# apollo3p register map
Vendor: Ambiq Micro; Series: Apollo; File version: 1.0
CPU: CM4 r1p0, little endian, MPU, FPU, I-cache, D-cache, VTOR, ITCM, DTCM, 3 interrupt priority bits, 0 interrupts
Registers are 32-bit, read-write, reset 0x0 unless marked. A register's access mark holds for its fields unless they carry their own. Offsets are from the block's base; [hi:lo] are bit positions; {n}, {i} and the like mark numbered series; 'fields as' and 'values as' point back to an identical list.

## CTIMER (part 1 of 3) — Counter/Timer
Base 0x40008000
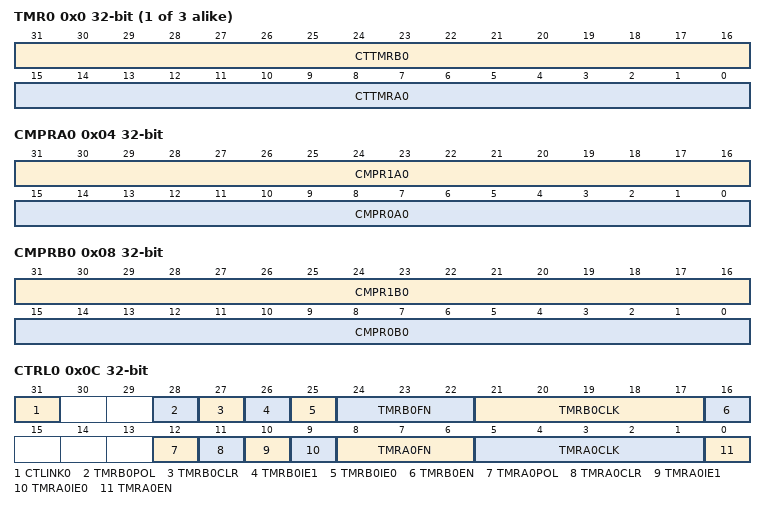
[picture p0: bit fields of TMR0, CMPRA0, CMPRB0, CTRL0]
{0x0+0x20*i} TMR{i} (i=0..2) — This register holds the running time or event count for CTIMER {i}. This is either for each 16 bit half or for the whole 32 bit count when the pair is linked. If the pair is not linked, they can be running on separate clocks and are completely independent.
  [31:16] CTTMRB{i} — Counter/Timer B{i}.
  [15:0] CTTMRA{i} — Counter/Timer A{i}.
0x04 CMPRA0 — This contains the Compare limits for timer 0 half A.
  [31:16] CMPR1A0 — Counter/Timer A0 Compare Register 1. Holds the upper limit for timer half A.
  [15:0] CMPR0A0 — Counter/Timer A0 Compare Register 0. Holds the lower limit for timer half A.
0x08 CMPRB0 — This contains the Compare limits for timer 0 B half.
  [31:16] CMPR1B0 — Counter/Timer B0 Compare Register 1. Holds the upper limit for timer half B.
  [15:0] CMPR0B0 — Counter/Timer B0 Compare Register 0. Holds the lower limit for timer half B.
0x0C CTRL0 — This includes the Control bit fields for both halves of timer 0.
  [31] CTLINK0 — Counter/Timer A0/B0 Link bit.
    0=TWO_16BIT_TIMERS (Use A0/B0 timers as two independent 16-bit timers (default).); 1=32BIT_TIMER (Link A0/B0 timers into a single 32-bit timer.)
  [28] TMRB0POL — Counter/Timer B0 output polarity.
    0=NORMAL (The polarity of the TMRPINB0 pin is the same as the timer output.); 1=INVERTED (The polarity of the TMRPINB0 pin is the inverse of the timer output.)
  [27] TMRB0CLR — Counter/Timer B0 Clear bit.
    0=RUN (Allow counter/timer B0 to run); 1=CLEAR (Holds counter/timer B0 at 0x0000.)
  [26] TMRB0IE1 — Counter/Timer B0 Interrupt Enable bit for COMPR1.
    0=DIS (Disable counter/timer B0 from generating an interrupt based on COMPR1.); 1=EN (Enable counter/timer B0 to generate an interrupt based on COMPR1.)
  [25] TMRB0IE0 — Counter/Timer B0 Interrupt Enable bit for COMPR0.
    0=DIS (Disable counter/timer B0 from generating an interrupt based on COMPR0.); 1=EN (Enable counter/timer B0 to generate an interrupt based on COMPR0)
  [24:22] TMRB0FN — Counter/Timer B0 Function Select.
    0=SINGLECOUNT (Single count (output toggles and sticks). Count to CMPR0B0, stop.); 1=REPEATEDCOUNT (Repeated count (periodic 1-clock-cycle-wide pulses). Count to CMPR0B0, restart.); 2=PULSE_ONCE (Pulse once (aka one-shot). Count to CMPR0B0, assert, count to CMPR1B0, deassert, stop.); 3=PULSE_CONT (Pulse continuously. Count to CMPR0B0, assert, count to CMPR1B0, deassert, restart.); 4=SINGLEPATTERN; 5=REPEATPATTERN (Repeated pattern.); 6=CONTINUOUS (Continuous run (aka Free Run). Count continuously.); 7=ALTPWN (Alternate PWM)
  [21:17] TMRB0CLK — Counter/Timer B0 Clock Select.
    0=TMRPIN (Clock source is TMRPINB.); 1=HFRC_DIV4 (Clock source is the HFRC / 4); 2=HFRC_DIV16 (Clock source is HFRC / 16); 3=HFRC_DIV256 (Clock source is HFRC / 256); 4=HFRC_DIV1024 (Clock source is HFRC / 1024); 5=HFRC_DIV4K (Clock source is HFRC / 4096); 6=XT (Clock source is the XT (uncalibrated).); 7=XT_DIV2 (Clock source is XT / 2); 8=XT_DIV16 (Clock source is XT / 16); 9=XT_DIV128 (Clock source is XT / 128); 10=LFRC_DIV2 (Clock source is LFRC / 2); 11=LFRC_DIV32 (Clock source is LFRC / 32); 12=LFRC_DIV1K (Clock source is LFRC / 1024); 13=LFRC (Clock source is LFRC); 14=RTC_100HZ (Clock source is 100 Hz from the current RTC oscillator.); 15=HCLK_DIV4 (Clock source is HCLK / 4 (note: this clock is only available when MCU is in active mode)); 16=XT_DIV4 (Clock source is XT / 4); 17=XT_DIV8 (Clock source is XT / 8); 18=XT_DIV32 (Clock source is XT / 32); 20=CTMRA0 (Clock source is CTIMERA0 OUT.); 21=CTMRB1 (Clock source is CTIMERB1 OUT.); 22=CTMRA1 (Clock source is CTIMERA1 OUT.); 23=CTMRA2 (Clock source is CTIMERA2 OUT.); {v}=CTMRB{v-22} (Clock source is CTIMERB{v-22} OUT.) (v=24..28); 29=BUCKBLE (Clock source is BLE buck converter TON pulses.); 30=BUCKB (Clock source is Memory buck converter TON pulses.); 31=BUCKA (Clock source is CPU buck converter TON pulses.)
  [16] TMRB0EN — Counter/Timer B0 Enable bit.
    0=DIS (Counter/Timer B0 Disable.); 1=EN (Counter/Timer B0 Enable.)
  [12] TMRA0POL — Counter/Timer A0 output polarity.
    0=NORMAL (The polarity of the TMRPINA0 pin is the same as the timer output.); 1=INVERTED (The polarity of the TMRPINA0 pin is the inverse of the timer output.)
  [11] TMRA0CLR — Counter/Timer A0 Clear bit.
    0=RUN (Allow counter/timer A0 to run); 1=CLEAR (Holds counter/timer A0 at 0x0000.)
  [10] TMRA0IE1 — Counter/Timer A0 Interrupt Enable bit based on COMPR1.
    0=DIS (Disable counter/timer A0 from generating an interrupt based on COMPR1.); 1=EN (Enable counter/timer A0 to generate an interrupt based on COMPR1.)
  [9] TMRA0IE0 — Counter/Timer A0 Interrupt Enable bit based on COMPR0.
    0=DIS (Disable counter/timer A0 from generating an interrupt based on COMPR0.); 1=EN (Enable counter/timer A0 to generate an interrupt based on COMPR0.)
  [8:6] TMRA0FN — Counter/Timer A0 Function Select.
    0=SINGLECOUNT (Single count (output toggles and sticks). Count to CMPR0A0, stop.); 1=REPEATEDCOUNT (Repeated count (periodic 1-clock-cycle-wide pulses). Count to CMPR0A0, restart.); 2=PULSE_ONCE (Pulse once (aka one-shot). Count to CMPR0A0, assert, count to CMPR1A0, deassert, stop.); 3=PULSE_CONT (Pulse continuously. Count to CMPR0A0, assert, count to CMPR1A0, deassert, restart.); 4=SINGLEPATTERN; 5=REPEATPATTERN (Repeated pattern.); 6=CONTINUOUS (Continuous run (aka Free Run). Count continuously.); 7=ALTPWN (Alternate PWM)
  [5:1] TMRA0CLK — Counter/Timer A0 Clock Select.
    0=TMRPIN (Clock source is TMRPINA.); 1=HFRC_DIV4 (Clock source is the HFRC / 4); 2=HFRC_DIV16 (Clock source is HFRC / 16); 3=HFRC_DIV256 (Clock source is HFRC / 256); 4=HFRC_DIV1024 (Clock source is HFRC / 1024); 5=HFRC_DIV4K (Clock source is HFRC / 4096); 6=XT (Clock source is the XT (uncalibrated).); 7=XT_DIV2 (Clock source is XT / 2); 8=XT_DIV16 (Clock source is XT / 16); 9=XT_DIV128 (Clock source is XT / 128); 10=LFRC_DIV2 (Clock source is LFRC / 2); 11=LFRC_DIV32 (Clock source is LFRC / 32); 12=LFRC_DIV1K (Clock source is LFRC / 1024); 13=LFRC (Clock source is LFRC); 14=RTC_100HZ (Clock source is 100 Hz from the current RTC oscillator.); 15=HCLK_DIV4 (Clock source is HCLK / 4 (note: this clock is only available when MCU is in active mode)); 16=XT_DIV4 (Clock source is XT / 4); 17=XT_DIV8 (Clock source is XT / 8); 18=XT_DIV32 (Clock source is XT / 32); 20=CTMRB0 (Clock source is CTIMERB0 OUT.); 21=CTMRA1 (Clock source is CTIMERA1 OUT.); 22=CTMRB1 (Clock source is CTIMERB1 OUT.); 23=CTMRA2 (Clock source is CTIMERA2 OUT.); {v}=CTMRB{v-22} (Clock source is CTIMERB{v-22} OUT.) (v=24..28); 29=BUCKBLE (Clock source is BLE buck converter TON pulses.); 30=BUCKB (Clock source is Memory buck converter TON pulses.); 31=BUCKA (Clock source is CPU buck converter TON pulses.)
  [0] TMRA0EN — Counter/Timer A0 Enable bit.
    0=DIS (Counter/Timer A0 Disable.); 1=EN (Counter/Timer A0 Enable.)
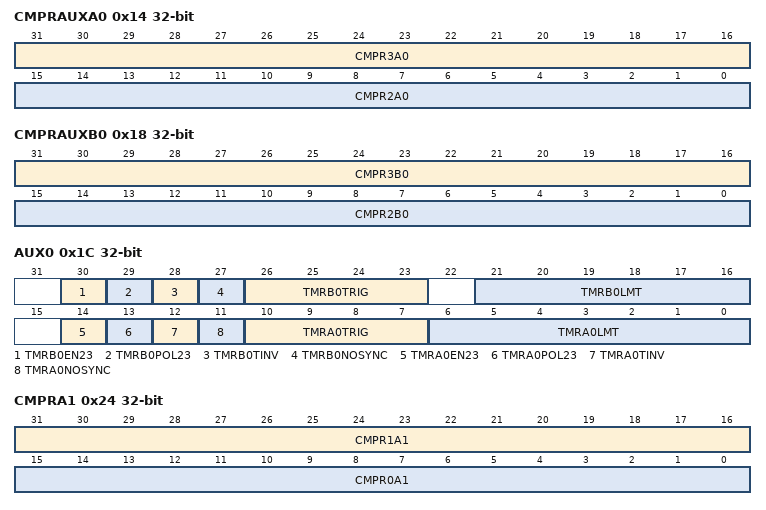
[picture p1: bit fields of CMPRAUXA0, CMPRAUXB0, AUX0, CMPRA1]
0x14 CMPRAUXA0 — Enhanced compare limits for timer half A. This is valid if timer 0 is set to function 4 and function 5.
  [31:16] CMPR3A0 — Counter/Timer A0 Compare Register 3. Holds the upper limit for timer half A.
  [15:0] CMPR2A0 — Counter/Timer A0 Compare Register 2. Holds the lower limit for timer half A.
0x18 CMPRAUXB0 — Enhanced compare limits for timer half B. This is valid if timer 0 is set to function 4 and function 5.
  [31:16] CMPR3B0 — Counter/Timer B0 Compare Register 3. Holds the upper limit for timer half B.
  [15:0] CMPR2B0 — Counter/Timer B0 Compare Register 2. Holds the lower limit for timer half B.
0x1C AUX0 — Control bit fields for both halves of timer 0.
  [30] TMRB0EN23 — Counter/Timer B0 Upper compare enable.
    1=DIS (Disable enhanced functions.); 0=EN (Enable enhanced functions.)
  [29] TMRB0POL23 — Upper output polarity
    0=NORM (Upper output normal polarity); 1=INV (Upper output inverted polarity.)
  [28] TMRB0TINV — Counter/Timer B0 Invert on trigger.
    0=DIS (Disable invert on trigger); 1=EN (Enable invert on trigger)
  [27] TMRB0NOSYNC — Source clock synchronization control.
    0=DIS (Synchronization on source clock); 1=NOSYNC (No synchronization on source clock)
  [26:23] TMRB0TRIG — Counter/Timer B0 Trigger Select.
    0=DIS (Trigger source is disabled.); 1=A0OUT (Trigger source is CTIMERA0 OUT.); 2=B3OUT (Trigger source is CTIMERB3 OUT.); 3=A3OUT (Trigger source is CTIMERA3 OUT.); 4=B2OUT (Trigger source is CTIMERB2 OUT.); 5=B5OUT (Trigger source is CTIMERB5 OUT.); 6=A4OUT (Trigger source is CTIMERA4 OUT.); 7=B4OUT (Trigger source is CTIMERB4 OUT.); 8=B3OUT2 (Trigger source is CTIMERB3 OUT2.); 9=A3OUT2 (Trigger source is CTIMERA3 OUT2.); 10=B7OUT2 (Trigger source is CTIMERB7 OUT2.); 11=A2OUT2 (Trigger source is CTIMERA2 OUT2.); 12=A6OUT2DUAL (Trigger source is CTIMERA6 OUT2, dual edge.); 13=A7OUT2DUAL (Trigger source is CTIMERA7 OUT2, dual edge.); 14=B5OUT2DUAL (Trigger source is CTIMERB5 OUT2, dual edge.); 15=A5OUT2DUAL (Trigger source is CTIMERA5 OUT2, dual edge.)
  [21:16] TMRB0LMT — Counter/Timer B0 Pattern Limit Count.
  [14] TMRA0EN23 — Counter/Timer A0 Upper compare enable.
    values as TMRB0EN23
  [13] TMRA0POL23 — Counter/Timer A0 Upper output polarity
    values as TMRB0POL23
  [12] TMRA0TINV — Counter/Timer A0 Invert on trigger.
    values as TMRB0TINV
  [11] TMRA0NOSYNC — Source clock synchronization control.
    values as TMRB0NOSYNC
  [10:7] TMRA0TRIG — Counter/Timer A0 Trigger Select.
    0=DIS (Trigger source is disabled.); 1=B0OUT (Trigger source is CTIMERB0 OUT.); 2=B3OUT (Trigger source is CTIMERB3 OUT.); 3=A3OUT (Trigger source is CTIMERA3 OUT.); 4=A1OUT (Trigger source is CTIMERA1 OUT.); 5=B1OUT (Trigger source is CTIMERB1 OUT.); 6=A5OUT (Trigger source is CTIMERA5 OUT.); 7=B5OUT (Trigger source is CTIMERB5 OUT.); 8=B3OUT2 (Trigger source is CTIMERB3 OUT2.); 9=A3OUT2 (Trigger source is CTIMERA3 OUT2.); 10=B6OUT2 (Trigger source is CTIMERB6 OUT2.); 11=A2OUT2 (Trigger source is CTIMERA2 OUT2.); 12=A6OUT2DUAL (Trigger source is CTIMERA6 OUT2, dual edge.); 13=A7OUT2DUAL (Trigger source is CTIMERA7 OUT2, dual edge.); 14=B4OUT2DUAL (Trigger source is CTIMERB4 OUT2, dual edge.); 15=A4OUT2DUAL (Trigger source is CTIMERA4 OUT2, dual edge.)
  [6:0] TMRA0LMT — Counter/Timer A0 Pattern Limit Count.
0x24 CMPRA1 — This contains the Compare limits for timer 1 A half.
  [31:16] CMPR1A1 — Counter/Timer A1 Compare Register 1.
  [15:0] CMPR0A1 — Counter/Timer A1 Compare Register 0.
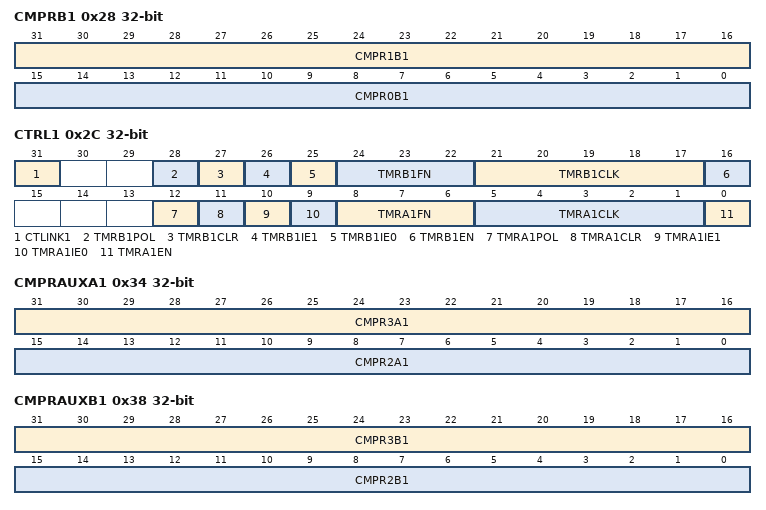
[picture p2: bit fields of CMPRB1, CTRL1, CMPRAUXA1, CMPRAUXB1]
0x28 CMPRB1 — This contains the Compare limits for timer 1 B half.
  [31:16] CMPR1B1 — Counter/Timer B1 Compare Register 1.
  [15:0] CMPR0B1 — Counter/Timer B1 Compare Register 0.
0x2C CTRL1 — This includes the Control bit fields for both halves of timer 1.
  [31] CTLINK1 — Counter/Timer A1/B1 Link bit.
    0=TWO_16BIT_TIMERS (Use A1/B1 timers as two independent 16-bit timers (default).); 1=32BIT_TIMER (Link A1/B1 timers into a single 32-bit timer.)
  [28] TMRB1POL — Counter/Timer B1 output polarity.
    0=NORMAL (The polarity of the TMRPINB1 pin is the same as the timer output.); 1=INVERTED (The polarity of the TMRPINB1 pin is the inverse of the timer output.)
  [27] TMRB1CLR — Counter/Timer B1 Clear bit.
    0=RUN (Allow counter/timer B1 to run); 1=CLEAR (Holds counter/timer B1 at 0x0000.)
  [26] TMRB1IE1 — Counter/Timer B1 Interrupt Enable bit for COMPR1.
    0=DIS (Disable counter/timer B1 from generating an interrupt based on COMPR1.); 1=EN (Enable counter/timer B1 to generate an interrupt based on COMPR1.)
  [25] TMRB1IE0 — Counter/Timer B1 Interrupt Enable bit for COMPR0.
    0=DIS (Disable counter/timer B1 from generating an interrupt based on COMPR0.); 1=EN (Enable counter/timer B1 to generate an interrupt based on COMPR0)
  [24:22] TMRB1FN — Counter/Timer B1 Function Select.
    0=SINGLECOUNT (Single count (output toggles and sticks). Count to CMPR0B1, stop.); 1=REPEATEDCOUNT (Repeated count (periodic 1-clock-cycle-wide pulses). Count to CMPR0B1, restart.); 2=PULSE_ONCE (Pulse once (aka one-shot). Count to CMPR0B1, assert, count to CMPR1B1, deassert, stop.); 3=PULSE_CONT (Pulse continuously. Count to CMPR0B1, assert, count to CMPR1B1, deassert, restart.); 4=SINGLEPATTERN; 5=REPEATPATTERN (Repeated pattern.); 6=CONTINUOUS (Continuous run (aka Free Run). Count continuously.); 7=ALTPWN (Alternate PWM)
  [21:17] TMRB1CLK — Counter/Timer B1 Clock Select.
    0=TMRPIN (Clock source is TMRPINB.); 1=HFRC_DIV4 (Clock source is the HFRC / 4); 2=HFRC_DIV16 (Clock source is HFRC / 16); 3=HFRC_DIV256 (Clock source is HFRC / 256); 4=HFRC_DIV1024 (Clock source is HFRC / 1024); 5=HFRC_DIV4K (Clock source is HFRC / 4096); 6=XT (Clock source is the XT (uncalibrated).); 7=XT_DIV2 (Clock source is XT / 2); 8=XT_DIV16 (Clock source is XT / 16); 9=XT_DIV128 (Clock source is XT / 128); 10=LFRC_DIV2 (Clock source is LFRC / 2); 11=LFRC_DIV32 (Clock source is LFRC / 32); 12=LFRC_DIV1K (Clock source is LFRC / 1024); 13=LFRC (Clock source is LFRC); 14=RTC_100HZ (Clock source is 100 Hz from the current RTC oscillator.); 15=HCLK_DIV4 (Clock source is HCLK / 4 (note: this clock is only available when MCU is in active mode)); 16=XT_DIV4 (Clock source is XT / 4); 17=XT_DIV8 (Clock source is XT / 8); 18=XT_DIV32 (Clock source is XT / 32); 20=CTMRA1 (Clock source is CTIMERA1 OUT.); 21=CTMRA0 (Clock source is CTIMERA0 OUT.); 22=CTMRB0 (Clock source is CTIMERB0 OUT.); 23=CTMRA2 (Clock source is CTIMERA2 OUT.); {v}=CTMRB{v-22} (Clock source is CTIMERB{v-22} OUT.) (v=24..28); 29=BUCKBLE (Clock source is BLE buck converter TON pulses.); 30=BUCKB (Clock source is Memory buck converter TON pulses.); 31=BUCKA (Clock source is CPU buck converter TON pulses.)
  [16] TMRB1EN — Counter/Timer B1 Enable bit.
    0=DIS (Counter/Timer B1 Disable.); 1=EN (Counter/Timer B1 Enable.)
  [12] TMRA1POL — Counter/Timer A1 output polarity.
    0=NORMAL (The polarity of the TMRPINA1 pin is the same as the timer output.); 1=INVERTED (The polarity of the TMRPINA1 pin is the inverse of the timer output.)
  [11] TMRA1CLR — Counter/Timer A1 Clear bit.
    0=RUN (Allow counter/timer A1 to run); 1=CLEAR (Holds counter/timer A1 at 0x0000.)
  [10] TMRA1IE1 — Counter/Timer A1 Interrupt Enable bit based on COMPR1.
    0=DIS (Disable counter/timer A1 from generating an interrupt based on COMPR1.); 1=EN (Enable counter/timer A1 to generate an interrupt based on COMPR1.)
  [9] TMRA1IE0 — Counter/Timer A1 Interrupt Enable bit based on COMPR0.
    0=DIS (Disable counter/timer A1 from generating an interrupt based on COMPR0.); 1=EN (Enable counter/timer A1 to generate an interrupt based on COMPR0.)
  [8:6] TMRA1FN — Counter/Timer A1 Function Select.
    0=SINGLECOUNT (Single count (output toggles and sticks). Count to CMPR0A1, stop.); 1=REPEATEDCOUNT (Repeated count (periodic 1-clock-cycle-wide pulses). Count to CMPR0A1, restart.); 2=PULSE_ONCE (Pulse once (aka one-shot). Count to CMPR0A1, assert, count to CMPR1A1, deassert, stop.); 3=PULSE_CONT (Pulse continuously. Count to CMPR0A1, assert, count to CMPR1A1, deassert, restart.); 4=SINGLEPATTERN; 5=REPEATPATTERN (Repeated pattern.); 6=CONTINUOUS (Continuous run (aka Free Run). Count continuously.); 7=ALTPWN (Alternate PWM)
  [5:1] TMRA1CLK — Counter/Timer A1 Clock Select.
    0=TMRPIN (Clock source is TMRPINA.); 1=HFRC_DIV4 (Clock source is the HFRC / 4); 2=HFRC_DIV16 (Clock source is HFRC / 16); 3=HFRC_DIV256 (Clock source is HFRC / 256); 4=HFRC_DIV1024 (Clock source is HFRC / 1024); 5=HFRC_DIV4K (Clock source is HFRC / 4096); 6=XT (Clock source is the XT (uncalibrated).); 7=XT_DIV2 (Clock source is XT / 2); 8=XT_DIV16 (Clock source is XT / 16); 9=XT_DIV128 (Clock source is XT / 128); 10=LFRC_DIV2 (Clock source is LFRC / 2); 11=LFRC_DIV32 (Clock source is LFRC / 32); 12=LFRC_DIV1K (Clock source is LFRC / 1024); 13=LFRC (Clock source is LFRC); 14=RTC_100HZ (Clock source is 100 Hz from the current RTC oscillator.); 15=HCLK_DIV4 (Clock source is HCLK / 4 (note: this clock is only available when MCU is in active mode)); 16=XT_DIV4 (Clock source is XT / 4); 17=XT_DIV8 (Clock source is XT / 8); 18=XT_DIV32 (Clock source is XT / 32); 20=CTMRB1 (Clock source is CTIMERB1 OUT.); 21=CTMRA0 (Clock source is CTIMERA0 OUT.); 22=CTMRB0 (Clock source is CTIMERB0 OUT.); 23=CTMRA2 (Clock source is CTIMERA2 OUT.); {v}=CTMRB{v-22} (Clock source is CTIMERB{v-22} OUT.) (v=24..28); 29=BUCKBLE (Clock source is BLE buck converter TON pulses.); 30=BUCKB (Clock source is Memory buck converter TON pulses.); 31=BUCKA (Clock source is CPU buck converter TON pulses.)
  [0] TMRA1EN — Counter/Timer A1 Enable bit.
    0=DIS (Counter/Timer A1 Disable.); 1=EN (Counter/Timer A1 Enable.)
0x34 CMPRAUXA1 — Enhanced compare limits for timer half A. This is valid if timer 1 is set to function 4 and function 5.
  [31:16] CMPR3A1 — Counter/Timer A1 Compare Register 3. Holds the upper limit for timer half A.
  [15:0] CMPR2A1 — Counter/Timer A1 Compare Register 2. Holds the lower limit for timer half A.
0x38 CMPRAUXB1 — Enhanced compare limits for timer half B. This is valid if timer 1 is set to function 4 and function 5.
  [31:16] CMPR3B1 — Counter/Timer B1 Compare Register 3. Holds the upper limit for timer half B.
  [15:0] CMPR2B1 — Counter/Timer B1 Compare Register 2. Holds the lower limit for timer half B.
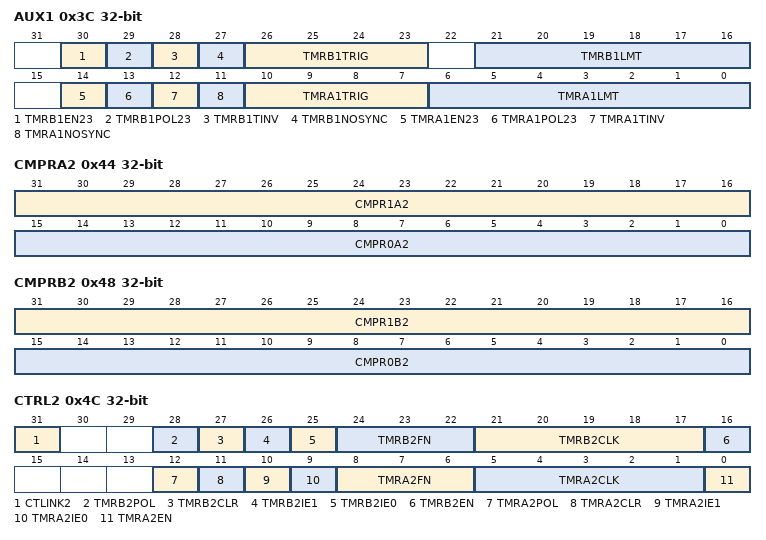
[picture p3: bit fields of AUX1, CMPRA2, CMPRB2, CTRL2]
0x3C AUX1 — Control bit fields for both halves of timer 0.
  [30] TMRB1EN23 — Counter/Timer B1 Upper compare enable.
    values as AUX0.TMRB0EN23
  [29] TMRB1POL23 — Upper output polarity
    values as AUX0.TMRB0POL23
  [28] TMRB1TINV — Counter/Timer B1 Invert on trigger.
    values as AUX0.TMRB0TINV
  [27] TMRB1NOSYNC — Source clock synchronization control.
    values as AUX0.TMRB0NOSYNC
  [26:23] TMRB1TRIG — Counter/Timer B1 Trigger Select.
    0=DIS (Trigger source is disabled.); 1=A1OUT (Trigger source is CTIMERA1 OUT.); 2=B3OUT (Trigger source is CTIMERB3 OUT.); 3=A3OUT (Trigger source is CTIMERA3 OUT.); 4=A6OUT (Trigger source is CTIMERA6 OUT.); 5=B6OUT (Trigger source is CTIMERB6 OUT.); 6=A0OUT (Trigger source is CTIMERA0 OUT.); 7=B0OUT (Trigger source is CTIMERB0 OUT.); 8=B3OUT2 (Trigger source is CTIMERB3 OUT2.); 9=A3OUT2 (Trigger source is CTIMERA3 OUT2.); 10=A4OUT2 (Trigger source is CTIMERA4 OUT2.); 11=B4OUT2 (Trigger source is CTIMERB4 OUT2.); 12=A6OUT2DUAL (Trigger source is CTIMERA6 OUT2, dual edge.); 13=A7OUT2DUAL (Trigger source is CTIMERA7 OUT2, dual edge.); 14=B5OUT2DUAL (Trigger source is CTIMERB5 OUT2, dual edge.); 15=A5OUT2DUAL (Trigger source is CTIMERA5 OUT2, dual edge.)
  [21:16] TMRB1LMT — Counter/Timer B1 Pattern Limit Count.
  [14] TMRA1EN23 — Counter/Timer A1 Upper compare enable.
    values as AUX0.TMRB0EN23
  [13] TMRA1POL23 — Counter/Timer A1 Upper output polarity
    0=NORMAL (Upper output normal polarity); 1=INV (Upper output inverted polarity.)
  [12] TMRA1TINV — Counter/Timer A1 Invert on trigger.
    values as AUX0.TMRB0TINV
  [11] TMRA1NOSYNC — Source clock synchronization control.
    values as AUX0.TMRB0NOSYNC
  [10:7] TMRA1TRIG — Counter/Timer A1 Trigger Select.
    0=DIS (Trigger source is disabled.); 1=B1OUT (Trigger source is CTIMERB1 OUT.); 2=B3OUT (Trigger source is CTIMERB3 OUT.); 3=A3OUT (Trigger source is CTIMERA3 OUT.); 4=A0OUT (Trigger source is CTIMERA0 OUT.); 5=B0OUT (Trigger source is CTIMERB0 OUT.); 6=A5OUT (Trigger source is CTIMERA5 OUT.); 7=B5OUT (Trigger source is CTIMERB5 OUT.); 8=B3OUT2 (Trigger source is CTIMERB3 OUT2.); 9=A3OUT2 (Trigger source is CTIMERA3 OUT2.); 10=A4OUT2 (Trigger source is CTIMERA4 OUT2.); 11=B4OUT2 (Trigger source is CTIMERB4 OUT2.); 12=A6OUT2DUAL (Trigger source is CTIMERA6 OUT2, dual edge.); 13=A7OUT2DUAL (Trigger source is CTIMERA7 OUT2, dual edge.); 14=B5OUT2DUAL (Trigger source is CTIMERB5 OUT2, dual edge.); 15=A5OUT2DUAL (Trigger source is CTIMERA5 OUT2, dual edge.)
  [6:0] TMRA1LMT — Counter/Timer A1 Pattern Limit Count.
0x44 CMPRA2 — This register holds the compare limits for timer 2 A half.
  [31:16] CMPR1A2 — Counter/Timer A2 Compare Register 1.
  [15:0] CMPR0A2 — Counter/Timer A2 Compare Register 0.
0x48 CMPRB2 — This register holds the compare limits for timer 2 B half.
  [31:16] CMPR1B2 — Counter/Timer B2 Compare Register 1.
  [15:0] CMPR0B2 — Counter/Timer B2 Compare Register 0.
0x4C CTRL2 — This register holds the control bit fields for both halves of timer 2.
  [31] CTLINK2 — Counter/Timer A2/B2 Link bit.
    0=TWO_16BIT_TIMERS (Use A2/B2 timers as two independent 16-bit timers (default).); 1=32BIT_TIMER (Link A2/B2 timers into a single 32-bit timer.)
  [28] TMRB2POL — Counter/Timer B2 output polarity.
    0=NORMAL (The polarity of the TMRPINB2 pin is the same as the timer output.); 1=INVERTED (The polarity of the TMRPINB2 pin is the inverse of the timer output.)
  [27] TMRB2CLR — Counter/Timer B2 Clear bit.
    0=RUN (Allow counter/timer B2 to run); 1=CLEAR (Holds counter/timer B2 at 0x0000.)
  [26] TMRB2IE1 — Counter/Timer B2 Interrupt Enable bit for COMPR1.
    0=DIS (Disable counter/timer B2 from generating an interrupt based on COMPR1.); 1=EN (Enable counter/timer B2 to generate an interrupt based on COMPR1.)
  [25] TMRB2IE0 — Counter/Timer B2 Interrupt Enable bit for COMPR0.
    0=DIS (Disable counter/timer B2 from generating an interrupt based on COMPR0.); 1=EN (Enable counter/timer B2 to generate an interrupt based on COMPR0)
  [24:22] TMRB2FN — Counter/Timer B2 Function Select.
    0=SINGLECOUNT (Single count (output toggles and sticks). Count to CMPR0B2, stop.); 1=REPEATEDCOUNT (Repeated count (periodic 1-clock-cycle-wide pulses). Count to CMPR0B2, restart.); 2=PULSE_ONCE (Pulse once (aka one-shot). Count to CMPR0B2, assert, count to CMPR1B2, deassert, stop.); 3=PULSE_CONT (Pulse continuously. Count to CMPR0B2, assert, count to CMPR1B2, deassert, restart.); 4=SINGLEPATTERN; 5=REPEATPATTERN (Repeated pattern.); 6=CONTINUOUS (Continuous run (aka Free Run). Count continuously.); 7=ALTPWN (Alternate PWM)
  [21:17] TMRB2CLK — Counter/Timer B2 Clock Select.
    0=TMRPIN (Clock source is TMRPINB.); 1=HFRC_DIV4 (Clock source is the HFRC / 4); 2=HFRC_DIV16 (Clock source is HFRC / 16); 3=HFRC_DIV256 (Clock source is HFRC / 256); 4=HFRC_DIV1024 (Clock source is HFRC / 1024); 5=HFRC_DIV4K (Clock source is HFRC / 4096); 6=XT (Clock source is the XT (uncalibrated).); 7=XT_DIV2 (Clock source is XT / 2); 8=XT_DIV16 (Clock source is XT / 16); 9=XT_DIV128 (Clock source is XT / 128); 10=LFRC_DIV2 (Clock source is LFRC / 2); 11=LFRC_DIV32 (Clock source is LFRC / 32); 12=LFRC_DIV1K (Clock source is LFRC / 1024); 13=LFRC (Clock source is LFRC); 14=RTC_100HZ (Clock source is 100 Hz from the current RTC oscillator.); 15=HCLK_DIV4 (Clock source is HCLK / 4 (note: this clock is only available when MCU is in active mode)); 16=XT_DIV4 (Clock source is XT / 4); 17=XT_DIV8 (Clock source is XT / 8); 18=XT_DIV32 (Clock source is XT / 32); 20=CTMRA2 (Clock source is CTIMERA2 OUT.); 21=CTMRB3 (Clock source is CTIMERA3 OUT.); 22=CTMRA3 (Clock source is CTIMERB3 OUT.); 23=CTMRA4 (Clock source is CTIMERA4 OUT.); 24=CTMRB4 (Clock source is CTIMERB4 OUT.); 25=CTMRB0 (Clock source is CTIMERB0 OUT.); 26=CTMRB1 (Clock source is CTIMERB1 OUT.); 27=CTMRB5 (Clock source is CTIMERB5 OUT.); 28=CTMRB6 (Clock source is CTIMERB6 OUT.); 29=BUCKBLE (Clock source is BLE buck converter TON pulses.); 30=BUCKB (Clock source is Memory buck converter TON pulses.); 31=BUCKA (Clock source is CPU buck converter TON pulses.)
  [16] TMRB2EN — Counter/Timer B2 Enable bit.
    0=DIS (Counter/Timer B2 Disable.); 1=EN (Counter/Timer B2 Enable.)
  [12] TMRA2POL — Counter/Timer A2 output polarity.
    0=NORMAL (The polarity of the TMRPINA2 pin is the same as the timer output.); 1=INVERTED (The polarity of the TMRPINA2 pin is the inverse of the timer output.)
  [11] TMRA2CLR — Counter/Timer A2 Clear bit.
    0=RUN (Allow counter/timer A2 to run); 1=CLEAR (Holds counter/timer A2 at 0x0000.)
  [10] TMRA2IE1 — Counter/Timer A2 Interrupt Enable bit based on COMPR1.
    0=DIS (Disable counter/timer A2 from generating an interrupt based on COMPR1.); 1=EN (Enable counter/timer A2 to generate an interrupt based on COMPR1.)
  [9] TMRA2IE0 — Counter/Timer A2 Interrupt Enable bit based on COMPR0.
    0=DIS (Disable counter/timer A2 from generating an interrupt based on COMPR0.); 1=EN (Enable counter/timer A2 to generate an interrupt based on COMPR0.)
  [8:6] TMRA2FN — Counter/Timer A2 Function Select.
    0=SINGLECOUNT (Single count (output toggles and sticks). Count to CMPR0A2, stop.); 1=REPEATEDCOUNT (Repeated count (periodic 1-clock-cycle-wide pulses). Count to CMPR0A2, restart.); 2=PULSE_ONCE (Pulse once (aka one-shot). Count to CMPR0A2, assert, count to CMPR1A2, deassert, stop.); 3=PULSE_CONT (Pulse continuously. Count to CMPR0A2, assert, count to CMPR1A2, deassert, restart.); 4=SINGLEPATTERN; 5=REPEATPATTERN (Repeated pattern.); 6=CONTINUOUS (Continuous run (aka Free Run). Count continuously.); 7=ALTPWN (Alternate PWM)
  [5:1] TMRA2CLK — Counter/Timer A2 Clock Select.
    0=TMRPIN (Clock source is TMRPINA.); 1=HFRC_DIV4 (Clock source is the HFRC / 4); 2=HFRC_DIV16 (Clock source is HFRC / 16); 3=HFRC_DIV256 (Clock source is HFRC / 256); 4=HFRC_DIV1024 (Clock source is HFRC / 1024); 5=HFRC_DIV4K (Clock source is HFRC / 4096); 6=XT (Clock source is the XT (uncalibrated).); 7=XT_DIV2 (Clock source is XT / 2); 8=XT_DIV16 (Clock source is XT / 16); 9=XT_DIV128 (Clock source is XT / 128); 10=LFRC_DIV2 (Clock source is LFRC / 2); 11=LFRC_DIV32 (Clock source is LFRC / 32); 12=LFRC_DIV1K (Clock source is LFRC / 1024); 13=LFRC (Clock source is LFRC); 14=RTC_100HZ (Clock source is 100 Hz from the current RTC oscillator.); 15=HCLK_DIV4 (Clock source is HCLK / 4 (note: this clock is only available when MCU is in active mode)); 16=XT_DIV4 (Clock source is XT / 4); 17=XT_DIV8 (Clock source is XT / 8); 18=XT_DIV32 (Clock source is XT / 32); 20=CTMRB2 (Clock source is CTIMERB2 OUT.); 21=CTMRB3 (Clock source is CTIMERA3 OUT.); 22=CTMRA3 (Clock source is CTIMERB3 OUT.); 23=CTMRA4 (Clock source is CTIMERA4 OUT.); 24=CTMRB4 (Clock source is CTIMERB4 OUT.); 25=CTMRB0 (Clock source is CTIMERB0 OUT.); 26=CTMRB1 (Clock source is CTIMERB1 OUT.); 27=CTMRB5 (Clock source is CTIMERB5 OUT.); 28=CTMRB6 (Clock source is CTIMERB6 OUT.); 29=BUCKBLE (Clock source is BLE buck converter TON pulses.); 30=BUCKB (Clock source is Memory buck converter TON pulses.); 31=BUCKA (Clock source is CPU buck converter TON pulses.)
  [0] TMRA2EN — Counter/Timer A2 Enable bit.
    0=DIS (Counter/Timer A2 Disable.); 1=EN (Counter/Timer A2 Enable.)
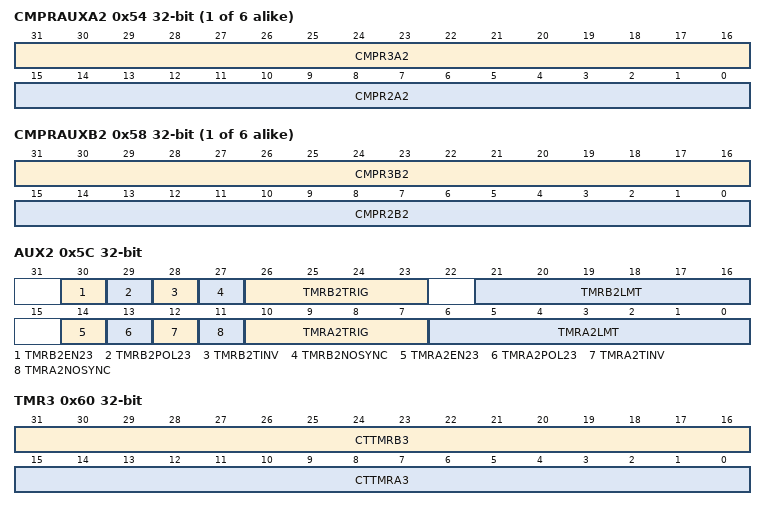
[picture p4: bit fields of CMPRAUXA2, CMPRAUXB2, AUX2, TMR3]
{0x14+0x20*i} CMPRAUXA{i} (i=2..7) — Enhanced compare limits for timer half A.
  [31:16] CMPR3A{i} — Counter/Timer A{i} Compare Register 3. Holds the upper limit for timer half A.
  [15:0] CMPR2A{i} — Counter/Timer A{i} Compare Register 2. Holds the lower limit for timer half A.
{0x18+0x20*i} CMPRAUXB{i} (i=2..7) — Enhanced compare limits for timer half B.
  [31:16] CMPR3B{i} — Counter/Timer B{i} Compare Register 3. Holds the upper limit for timer half B.
  [15:0] CMPR2B{i} — Counter/Timer B{i} Compare Register 2. Holds the lower limit for timer half B.
0x5C AUX2 — Control bit fields for both halves of timer 0.
  [30] TMRB2EN23 — Counter/Timer B2 Upper compare enable.
    values as AUX0.TMRB0EN23
  [29] TMRB2POL23 — Upper output polarity
    values as AUX0.TMRB0POL23
  [28] TMRB2TINV — Counter/Timer B2 Invert on trigger.
    values as AUX0.TMRB0TINV
  [27] TMRB2NOSYNC — Source clock synchronization control.
    values as AUX0.TMRB0NOSYNC
  [26:23] TMRB2TRIG — Counter/Timer B2 Trigger Select.
    0=DIS (Trigger source is disabled.); 1=A2OUT (Trigger source is CTIMERA2 OUT.); 2=B3OUT (Trigger source is CTIMERB3 OUT.); 3=A3OUT (Trigger source is CTIMERA3 OUT.); 4=A1OUT (Trigger source is CTIMERA1 OUT.); 5=B1OUT (Trigger source is CTIMERB1 OUT.); 6=A4OUT (Trigger source is CTIMERA4 OUT.); 7=B4OUT (Trigger source is CTIMERB4 OUT.); 8=B3OUT2 (Trigger source is CTIMERB3 OUT2.); 9=A3OUT2 (Trigger source is CTIMERA3 OUT2.); 10=A5OUT2 (Trigger source is CTIMERA5 OUT2.); 11=B5OUT2 (Trigger source is CTIMERB5 OUT2.); 12=A6OUT2DUAL (Trigger source is CTIMERA6 OUT2, dual edge.); 13=A7OUT2DUAL (Trigger source is CTIMERA7 OUT2, dual edge.); 14=B4OUT2DUAL (Trigger source is CTIMERB4 OUT2, dual edge.); 15=A4OUT2DUAL (Trigger source is CTIMERA4 OUT2, dual edge.)
  [21:16] TMRB2LMT — Counter/Timer B2 Pattern Limit Count.
  [14] TMRA2EN23 — Counter/Timer A2 Upper compare enable.
    values as AUX0.TMRB0EN23
  [13] TMRA2POL23 — Counter/Timer A2 Upper output polarity
    values as AUX0.TMRB0POL23
  [12] TMRA2TINV — Counter/Timer A2 Invert on trigger.
    values as AUX0.TMRB0TINV
  [11] TMRA2NOSYNC — Source clock synchronization control.
    values as AUX0.TMRB0NOSYNC
  [10:7] TMRA2TRIG — Counter/Timer A2 Trigger Select.
    0=DIS (Trigger source is disabled.); 1=B2OUT (Trigger source is CTIMERB2 OUT.); 2=B3OUT (Trigger source is CTIMERB3 OUT.); 3=A3OUT (Trigger source is CTIMERA3 OUT.); 4=A0OUT (Trigger source is CTIMERA0 OUT.); 5=B0OUT (Trigger source is CTIMERB0 OUT.); 6=A4OUT (Trigger source is CTIMERA4 OUT.); 7=B4OUT (Trigger source is CTIMERB4 OUT.); 8=B3OUT2 (Trigger source is CTIMERB3 OUT2.); 9=A3OUT2 (Trigger source is CTIMERA3 OUT2.); 10=A5OUT2 (Trigger source is CTIMERA5 OUT2.); 11=B5OUT2 (Trigger source is CTIMERB5 OUT2.); 12=A6OUT2DUAL (Trigger source is CTIMERA6 OUT2, dual edge.); 13=A7OUT2DUAL (Trigger source is CTIMERA7 OUT2, dual edge.); 14=B4OUT2DUAL (Trigger source is CTIMERB4 OUT2, dual edge.); 15=A4OUT2DUAL (Trigger source is CTIMERA4 OUT2, dual edge.)
  [6:0] TMRA2LMT — Counter/Timer A2 Pattern Limit Count.
0x60 TMR3 — Counter/Timer 3
  [31:16] CTTMRB3 — Counter/Timer B3.
  [15:0] CTTMRA3 — Counter/Timer A3.
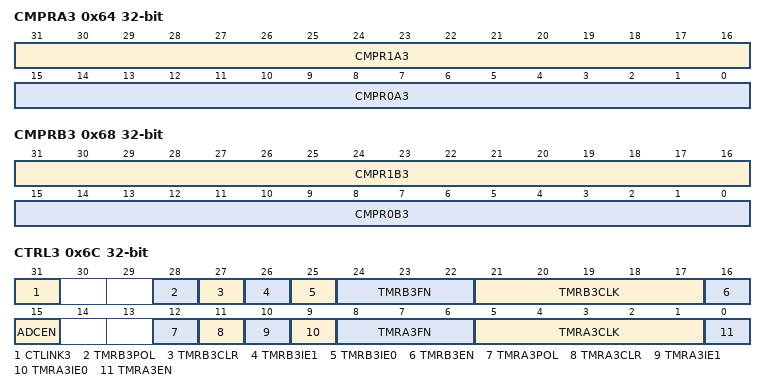
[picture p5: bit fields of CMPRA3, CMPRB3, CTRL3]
0x64 CMPRA3 — This register holds the compare limits for timer half A.
  [31:16] CMPR1A3 — Counter/Timer A3 Compare Register 1.
  [15:0] CMPR0A3 — Counter/Timer A3 Compare Register 0.
0x68 CMPRB3 — This register holds the compare limits for timer half B.
  [31:16] CMPR1B3 — Counter/Timer B3 Compare Register 1.
  [15:0] CMPR0B3 — Counter/Timer B3 Compare Register 0.
0x6C CTRL3 — This register holds the control bit fields for both halves of timer 3.
  [31] CTLINK3 — Counter/Timer A3/B3 Link bit.
    0=TWO_16BIT_TIMERS (Use A3/B3 timers as two independent 16-bit timers (default).); 1=32BIT_TIMER (Link A3/B3 timers into a single 32-bit timer.)
  [28] TMRB3POL — Counter/Timer B3 output polarity.
    0=NORMAL (The polarity of the TMRPINB3 pin is the same as the timer output.); 1=INVERTED (The polarity of the TMRPINB3 pin is the inverse of the timer output.)
  [27] TMRB3CLR — Counter/Timer B3 Clear bit.
    0=RUN (Allow counter/timer B3 to run); 1=CLEAR (Holds counter/timer B3 at 0x0000.)
  [26] TMRB3IE1 — Counter/Timer B3 Interrupt Enable bit for COMPR1.
    0=DIS (Disable counter/timer B3 from generating an interrupt based on COMPR1.); 1=EN (Enable counter/timer B3 to generate an interrupt based on COMPR1.)
  [25] TMRB3IE0 — Counter/Timer B3 Interrupt Enable bit for COMPR0.
    0=DIS (Disable counter/timer B3 from generating an interrupt based on COMPR0.); 1=EN (Enable counter/timer B3 to generate an interrupt based on COMPR0)
  [24:22] TMRB3FN — Counter/Timer B3 Function Select.
    0=SINGLECOUNT (Single count (output toggles and sticks). Count to CMPR0B3, stop.); 1=REPEATEDCOUNT (Repeated count (periodic 1-clock-cycle-wide pulses). Count to CMPR0B3, restart.); 2=PULSE_ONCE (Pulse once (aka one-shot). Count to CMPR0B3, assert, count to CMPR1B3, deassert, stop.); 3=PULSE_CONT (Pulse continuously. Count to CMPR0B3, assert, count to CMPR1B3, deassert, restart.); 4=SINGLEPATTERN; 5=REPEATPATTERN (Repeated pattern.); 6=CONTINUOUS (Continuous run (aka Free Run). Count continuously.); 7=ALTPWN (Alternate PWM)
  [21:17] TMRB3CLK — Counter/Timer B3 Clock Select.
    0=TMRPIN (Clock source is TMRPINB.); 1=HFRC_DIV4 (Clock source is the HFRC / 4); 2=HFRC_DIV16 (Clock source is HFRC / 16); 3=HFRC_DIV256 (Clock source is HFRC / 256); 4=HFRC_DIV1024 (Clock source is HFRC / 1024); 5=HFRC_DIV4K (Clock source is HFRC / 4096); 6=XT (Clock source is the XT (uncalibrated).); 7=XT_DIV2 (Clock source is XT / 2); 8=XT_DIV16 (Clock source is XT / 16); 9=XT_DIV128 (Clock source is XT / 128); 10=LFRC_DIV2 (Clock source is LFRC / 2); 11=LFRC_DIV32 (Clock source is LFRC / 32); 12=LFRC_DIV1K (Clock source is LFRC / 1024); 13=LFRC (Clock source is LFRC); 14=RTC_100HZ (Clock source is 100 Hz from the current RTC oscillator.); 15=HCLK_DIV4 (Clock source is HCLK / 4 (note: this clock is only available when MCU is in active mode)); 16=XT_DIV4 (Clock source is XT / 4); 17=XT_DIV8 (Clock source is XT / 8); 18=XT_DIV32 (Clock source is XT / 32); 20=CTMRA3 (Clock source is CTIMERA3 OUT.); 21=CTMRA2 (Clock source is CTIMERA2 OUT.); 22=CTMRB2 (Clock source is CTIMERB2 OUT.); 23=CTMRA4 (Clock source is CTIMERA4 OUT.); 24=CTMRB4 (Clock source is CTIMERB4 OUT.); 25=CTMRB0 (Clock source is CTIMERB0 OUT.); 26=CTMRB1 (Clock source is CTIMERB1 OUT.); 27=CTMRB5 (Clock source is CTIMERB5 OUT.); 28=CTMRB6 (Clock source is CTIMERB6 OUT.); 29=BUCKBLE (Clock source is BLE buck converter TON pulses.); 30=BUCKB (Clock source is Memory buck converter TON pulses.); 31=BUCKA (Clock source is CPU buck converter TON pulses.)
  [16] TMRB3EN — Counter/Timer B3 Enable bit.
    0=DIS (Counter/Timer B3 Disable.); 1=EN (Counter/Timer B3 Enable.)
  [15] ADCEN — Special Timer A3 enable for ADC function.
  [12] TMRA3POL — Counter/Timer A3 output polarity.
    0=NORMAL (The polarity of the TMRPINA3 pin is the same as the timer output.); 1=INVERTED (The polarity of the TMRPINA3 pin is the inverse of the timer output.)
  [11] TMRA3CLR — Counter/Timer A3 Clear bit.
    0=RUN (Allow counter/timer A3 to run); 1=CLEAR (Holds counter/timer A3 at 0x0000.)
  [10] TMRA3IE1 — Counter/Timer A3 Interrupt Enable bit based on COMPR1.
    0=DIS (Disable counter/timer A3 from generating an interrupt based on COMPR1.); 1=EN (Enable counter/timer A3 to generate an interrupt based on COMPR1.)
  [9] TMRA3IE0 — Counter/Timer A3 Interrupt Enable bit based on COMPR0.
    0=DIS (Disable counter/timer A3 from generating an interrupt based on COMPR0.); 1=EN (Enable counter/timer A3 to generate an interrupt based on COMPR0.)
  [8:6] TMRA3FN — Counter/Timer A3 Function Select.
    0=SINGLECOUNT (Single count (output toggles and sticks). Count to CMPR0A3, stop.); 1=REPEATEDCOUNT (Repeated count (periodic 1-clock-cycle-wide pulses). Count to CMPR0A3, restart.); 2=PULSE_ONCE (Pulse once (aka one-shot). Count to CMPR0A3, assert, count to CMPR1A3, deassert, stop.); 3=PULSE_CONT (Pulse continuously. Count to CMPR0A3, assert, count to CMPR1A3, deassert, restart.); 4=SINGLEPATTERN; 5=REPEATPATTERN (Repeated pattern.); 6=CONTINUOUS (Continuous run (aka Free Run). Count continuously.); 7=ALTPWN (Alternate PWM)
  [5:1] TMRA3CLK — Counter/Timer A3 Clock Select.
    0=TMRPIN (Clock source is TMRPINA.); 1=HFRC_DIV4 (Clock source is the HFRC / 4); 2=HFRC_DIV16 (Clock source is HFRC / 16); 3=HFRC_DIV256 (Clock source is HFRC / 256); 4=HFRC_DIV1024 (Clock source is HFRC / 1024); 5=HFRC_DIV4K (Clock source is HFRC / 4096); 6=XT (Clock source is the XT (uncalibrated).); 7=XT_DIV2 (Clock source is XT / 2); 8=XT_DIV16 (Clock source is XT / 16); 9=XT_DIV128 (Clock source is XT / 128); 10=LFRC_DIV2 (Clock source is LFRC / 2); 11=LFRC_DIV32 (Clock source is LFRC / 32); 12=LFRC_DIV1K (Clock source is LFRC / 1024); 13=LFRC (Clock source is LFRC); 14=RTC_100HZ (Clock source is 100 Hz from the current RTC oscillator.); 15=HCLK_DIV4 (Clock source is HCLK / 4 (note: this clock is only available when MCU is in active mode)); 16=XT_DIV4 (Clock source is XT / 4); 17=XT_DIV8 (Clock source is XT / 8); 18=XT_DIV32 (Clock source is XT / 32); 20=CTMRB3 (Clock source is CTIMERB3 OUT.); 21=CTMRA2 (Clock source is CTIMERA2 OUT.); 22=CTMRB2 (Clock source is CTIMERB2 OUT.); 23=CTMRA4 (Clock source is CTIMERA4 OUT.); 24=CTMRB4 (Clock source is CTIMERB4 OUT.); 25=CTMRB0 (Clock source is CTIMERB0 OUT.); 26=CTMRB1 (Clock source is CTIMERB1 OUT.); 27=CTMRB5 (Clock source is CTIMERB5 OUT.); 28=CTMRB6 (Clock source is CTIMERB6 OUT.); 29=BUCKBLE (Clock source is BLE buck converter TON pulses.); 30=BUCKB (Clock source is Memory buck converter TON pulses.); 31=BUCKA (Clock source is CPU buck converter TON pulses.)
  [0] TMRA3EN — Counter/Timer A3 Enable bit.
    0=DIS (Counter/Timer A3 Disable.); 1=EN (Counter/Timer A3 Enable.)

## Notices in the file
Copyright (C) 2012-2014 ARM Limited. All rights reserved.
Purpose: System Viewer Description (SVD) Example (Schema Version 1.1)
This is a description of a none-existent and incomplete device
for demonstration purposes only.
Redistribution and use in source and binary forms, with or without
modification, are permitted provided that the following conditions are met:
- Redistributions of source code must retain the above copyright
notice, this list of conditions and the following disclaimer.
- Redistributions in binary form must reproduce the above copyright
notice, this list of conditions and the following disclaimer in the
documentation and/or other materials provided with the distribution.
- Neither the name of ARM nor the names of its contributors may be used
to endorse or promote products derived from this software without
specific prior written permission.
THIS SOFTWARE IS PROVIDED BY THE COPYRIGHT HOLDERS AND CONTRIBUTORS "AS IS"
AND ANY EXPRESS OR IMPLIED WARRANTIES, INCLUDING, BUT NOT LIMITED TO, THE
IMPLIED WARRANTIES OF MERCHANTABILITY AND FITNESS FOR A PARTICULAR PURPOSE
ARE DISCLAIMED. IN NO EVENT SHALL COPYRIGHT HOLDERS AND CONTRIBUTORS BE
LIABLE FOR ANY DIRECT, INDIRECT, INCIDENTAL, SPECIAL, EXEMPLARY, OR
CONSEQUENTIAL DAMAGES (INCLUDING, BUT NOT LIMITED TO, PROCUREMENT OF
SUBSTITUTE GOODS OR SERVICES; LOSS OF USE, DATA, OR PROFITS; OR BUSINESS
INTERRUPTION) HOWEVER CAUSED AND ON ANY THEORY OF LIABILITY, WHETHER IN
CONTRACT, STRICT LIABILITY, OR TORT (INCLUDING NEGLIGENCE OR OTHERWISE)
ARISING IN ANY WAY OUT OF THE USE OF THIS SOFTWARE, EVEN IF ADVISED OF THE
POSSIBILITY OF SUCH DAMAGE.
